# headsail register map
Vendor: tuni.fi; File version: 1.1
CPU: other r1p0, little endian, no MPU, no FPU, vendor SysTick, 2 interrupt priority bits
Registers are 32-bit, read-write, no defined reset value unless marked. A register's access mark holds for its fields unless they carry their own. Offsets are from the block's base; [hi:lo] are bit positions; lines under a group give offsets from that group; {n}, {i} and the like mark numbered series.

## mdio_map0
Base 0x1FF400200
Same registers: mdio_map1 0x1FF400400
0x00 mdio group
  0x00 MDIO_CTRL reset 0x0
    [2:0] MDIO_CTRL
  0x04 MDIO_DIV reset 0xA
    [7:0] MDIO_DIV
  0x08 MDIO_WR_DATA reset 0x0
    [15:0] MDIO_WR_DATA
  0x0C MDIO_RD_DATA ro reset 0x0
    [15:0] MDIO_RD_DATA
  0x10 MDIO_STATUS ro reset 0x0
    [0] MDIO_STATUS
  0x14 MDIO_ADDR_ON_PHY reset 0x0
    [4:0] MDIO_ADDR_ON_PHY
  0x18 MDIO_ADDR_PHY reset 0x0
    [4:0] MDIO_ADDR_PHY

## apb_gpio
Base 0x1FFF04000
0x00 addressBlock group
  0x00 PADDIR — Pad Direction. Control the direction of each of the GPIO pads. A value of 1 means it is configured as an output, while 0 configures it as an input.
  0x04 PADIN wo — Input Values.
    [31:0] PADIN_0
  0x08 PADOUT — Output Values.
  0x0C INTEN — Interrupt Enable. Interrupt enable per input bit. INTTYPE0 and INTTYPE1 control the interrupt triggering behavior.
  0x10 INTTYPE0 — Interrupt Type 0. Controls the interrupt trigger behavior together with INTTYPE1. Use INTEN to enable interrupts first.
  0x14 INTTYPE1 — Interrupt Type 1. Controls the interrupt trigger behavior together with INTTYPE0. Use INTEN to enable interrupts first.
  0x18 INTSTATUS ro — Interrupt Status. Contains interrupt status per GPIO line. The status register is cleared when read. Similarly the interrupt line is high while a bit is set in interrupt status and will be deasserted when the status register is read.
  0x1C POWEREVENT
  {0x20+4j} PADCFG{j} (j=0..7) — Pad Configuration Registers. The pad configuration registers control various aspects of the pads that are typically used in ASICs, e.g. drive strength, Schmitt-Triggers, Slew Rate, etc. Since those configuration parameters depend on the exact pads used, each implementation is free to use the PADCFG0-7 registers in every way it wants and also leave them unconnected, if unneeded.

## apb_i2c
Base 0x1FFF05000
0x00 registers group
  0x00 CLK_PRESCALER — Clock Prescale Register
    [15:0] PRE — Sets the clock prescaler by the value in PRE to achieve the desired I2C clock by dividing
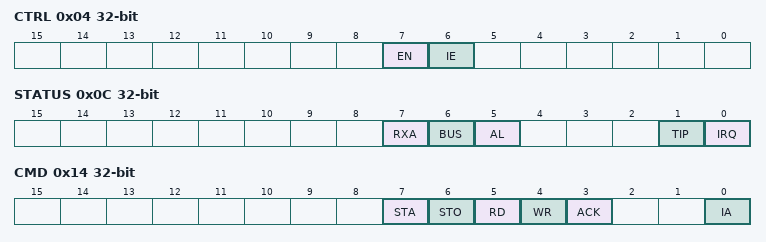
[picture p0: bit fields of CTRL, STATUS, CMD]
  0x04 CTRL — Control Register
    [7] EN — Enable the I2C peripheral.
    [6] IE — Enable interrupts
  0x08 RX ro — Receive Register
    [7:0] RX
  0x0C STATUS ro
    [7] RXA — Acknowledge from sent data
    [6] BUS — Bus is busy
    [5] AL — Arbitration lost.
    [1] TIP — Transfer in progress
    [0] IRQ — Interrupt received. This flag is always set when transmission has finished or bus arpitration was lostm, regardless of whether interrupts are enabled or not. This flag can possibly polled and is cleared by writing 1 to the IA command register.
  0x10 TX — Transmit Register
    [7:0] TX
  0x14 CMD — Command Register
    [7] STA — Send start bit
    [6] STO — Send stop bit
    [5] RD — Read from bus.
    [4] WR — Write to bus
    [3] ACK — Acknowledge received data
    [0] IA — Interrupt Acknowldge. Set to one to acknowledge interrupt. Cleared when transmission is done or arbitration is lost.

## apb_spim0
Base 0x1FFF02000
Same registers: apb_spim1 0x1FFF03000
0x00 registers group
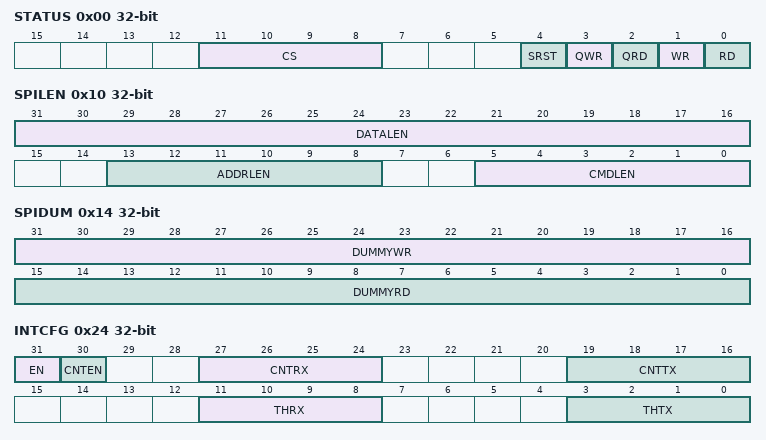
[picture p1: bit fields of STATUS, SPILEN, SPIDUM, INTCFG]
  0x00 STATUS
    [11:8] CS — Each one of these bits corresponds to one of the spi lines. Enable any of them to enable the cs on the corresponding spi line.
    [4] SRST — Assert this to clear the rx and tx FIFOs
    [3] QWR — Assert this for quad write mode
    [2] QRD — Assert this for quad read mode
    [1] WR — Assert this for write operation
    [0] RD — Assert this for read operation
  0x04 CLKDIV — Clock Divider
    [7:0] CLKDIV
  0x08 SPICMD — SPI Command
    [31:0] SPICMD — Insert the command to be transmitted
  0x0C SPIADR — SPI Address
    [31:0] SPIADR — Insert the address to be transmitted
  0x10 SPILEN — SPI Transfer Length
    [31:16] DATALEN — The number of data bits to be read or written.
    [13:8] ADDRLEN — The number of bits of the SPI address that should be sent.
    [5:0] CMDLEN — The number of bits of the SPI command that should be sent.
  0x14 SPIDUM — SPI Dummy Cycles
    [31:16] DUMMYWR — Dummy cycles (nothing being written or read) between sending the SPI command + SPI address and writing the data.
    [15:0] DUMMYRD — Dummy cycles (nothing being written or read) between sending the SPI command + SPI address and reading the data.
  0x18 TXFIFO wo — SPI Transmit FIFO
    [31:0] TX — Write data into the FIFO.
  0x20 RXFIFO ro — SPI Receive FIFO
    [31:0] RX — Read data from the FIFO.
  0x24 INTCFG — Interrupt Configuration
    [31] EN — Enable interrupt
    [30] CNTEN — Enable counter to enable the previous 2 functionalities
    [27:24] CNTRX — Specify the number of data words received before the assertion of events_o[0]
    [19:16] CNTTX — Specify the number of data words sent before the assertion of events_o[0]
    [11:8] THRX — Insert the number of elements in the rxfifo afterwhich the events_o[0] is high
    [3:0] THTX — Insert the number of elements in the txfifo before which the events_o[0] is high
  0x28 INTSTA ro — This register isn't properly specified so we need to look at this
    [31:0] INTSTA — Not used
